# STM32H5E5xx register map
File version: 1.0
Registers are 32-bit, read-write, reset 0x0 unless marked. A register's access mark holds for its fields unless they carry their own. Offsets are from the block's base; [hi:lo] are bit positions; {n}, {i} and the like mark numbered series.

## PWR — Power Control
Base 0x44020800
Same registers: PWR_S 0x54020800
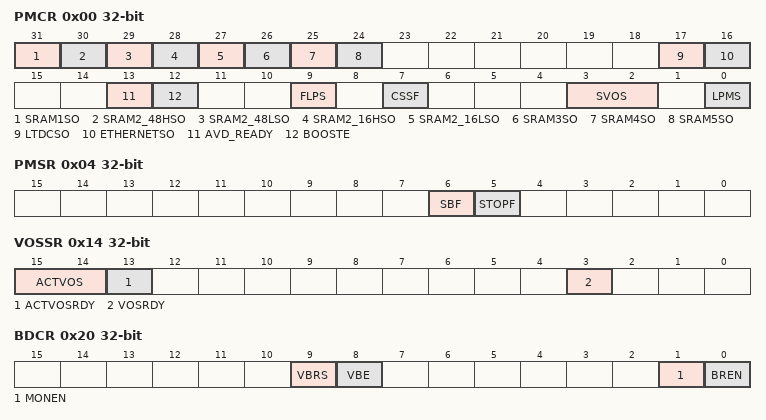
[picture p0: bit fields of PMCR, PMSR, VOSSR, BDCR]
0x00 PMCR — Power mode control register
  [31] SRAM1SO
  [30] SRAM2_48HSO
  [29] SRAM2_48LSO
  [28] SRAM2_16HSO
  [27] SRAM2_16LSO
  [26] SRAM3SO
  [25] SRAM4SO
  [24] SRAM5SO
  [17] LTDCSO
  [16] ETHERNETSO
  [13] AVD_READY
  [12] BOOSTE
  [9] FLPS
  [7] CSSF
  [3:2] SVOS
    3=SCALE3 (Select voltage scale 3 when system enters STOP mode); 2=SCALE4 (Select voltage scale 4 when system enters STOP mode); 1=SCALE5 (Select voltage scale 5 when system enters STOP mode)
  [0] LPMS
    0=STOP_MODE (STOP 0 mode); 1=STANDBY_MODE
0x04 PMSR — Power mode status register
  [6] SBF, [5] STOPF
0x10 VOSCR — Voltage scaling control register
  [5:4] VOS
    3=SCALE0 (Voltage scaling range 0); 2=SCALE1 (Voltage scaling range 1); 1=SCALE2 (Voltage scaling range 2); 0=SCALE3 (Voltage scaling range 3)
0x14 VOSSR — Voltage sacling status register
  [15:14] ACTVOS, [13] ACTVOSRDY, [3] VOSRDY
0x20 BDCR — BacKup domain control register
  [9] VBRS
    0=RESISTOR_5K (Charge the battery through a 5 kO resistor); 1=RESISTOR_1_5K (Charge the battery through a 1.5 kO resistor)
  [8] VBE
  [1] MONEN
  [0] BREN
0x24 DBPCR — DBP control register
  [0] DBP
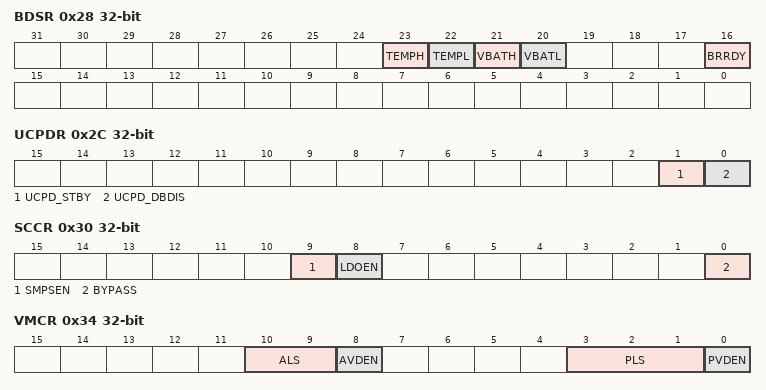
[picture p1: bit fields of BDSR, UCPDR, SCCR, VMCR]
0x28 BDSR — BacKup domain status register
  [23] TEMPH, [22] TEMPL, [21] VBATH, [20] VBATL, [16] BRRDY
0x2C UCPDR — Usb typeC and Power Delivery Register
  [1] UCPD_STBY, [0] UCPD_DBDIS
0x30 SCCR — Supply configuration control register
  [9] SMPSEN, [8] LDOEN, [0] BYPASS
0x34 VMCR — Voltage Monitor Control Register
  [10:9] ALS
    0=AVDLEVEL_0 (Analog Voltage threshold detected by AVD 1.7 V); 1=AVDLEVEL_1 (Analog Voltage threshold detected by AVD 2.1 V); 2=AVDLEVEL_2 (Analog Voltage threshold detected by AVD 2.5 V); 3=AVDLEVEL_3 (Analog Voltage threshold detected by AVD 2.8 V)
  [8] AVDEN
  [3:1] PLS
    0=PVDLEVEL_0 (Voltage threshold detected by PVD 1.95 V); 1=PVDLEVEL_1 (Voltage threshold detected by PVD 2.10 V); 2=PVDLEVEL_2 (Voltage threshold detected by PVD 2.25 V); 3=PVDLEVEL_3 (Voltage threshold detected by PVD 2.40 V); 4=PVDLEVEL_4 (Voltage threshold detected by PVD 2.55 V); 5=PVDLEVEL_5 (Voltage threshold detected by PVD 2.70 V); 6=PVDLEVEL_6 (Voltage threshold detected by PVD 2.85 V); 7=PVDLEVEL_7
  [0] PVDEN
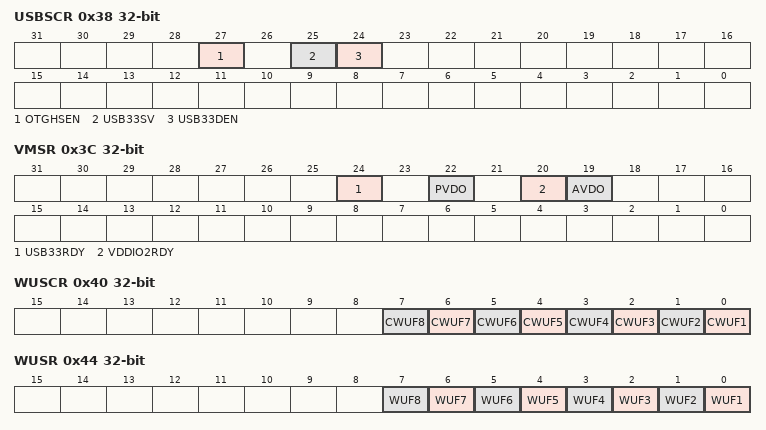
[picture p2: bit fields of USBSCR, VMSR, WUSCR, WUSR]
0x38 USBSCR — USB Supply Control Register
  [27] OTGHSEN, [25] USB33SV, [24] USB33DEN
0x3C VMSR — Status Register Voltage Monitoring
  [24] USB33RDY, [22] PVDO, [20] VDDIO2RDY, [19] AVDO
0x40 WUSCR — WakeUP status clear register
  [n-1] CWUF{n} (n=1..8)
0x44 WUSR — WakeUP status Register
  [n-1] WUF{n} (n=1..8)
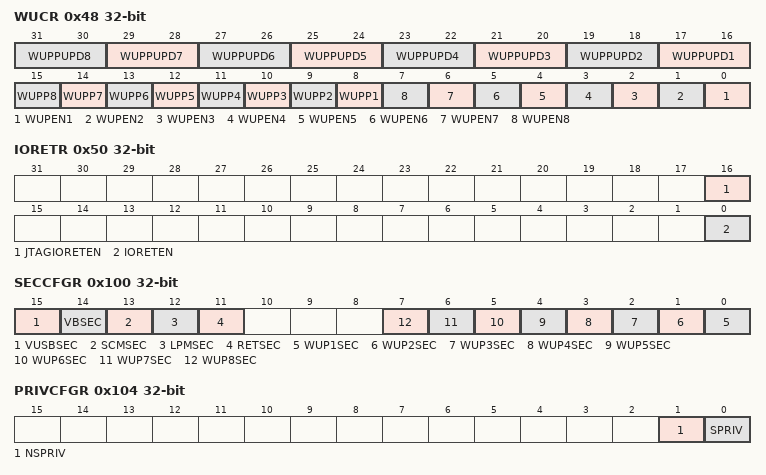
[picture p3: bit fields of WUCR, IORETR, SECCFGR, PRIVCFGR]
0x48 WUCR — WakeUP configuration register
  [2n+15:2n+14] WUPPUPD{n} (n=1..8), [n+7] WUPP{n} (n=1..8), [n-1] WUPEN{n} (n=1..8)
0x50 IORETR — IO RETention Register
  [16] JTAGIORETEN, [0] IORETEN
0x100 SECCFGR — Security configuration register
  [15] VUSBSEC, [14] VBSEC, [13] SCMSEC, [12] LPMSEC, [11] RETSEC, [n-1] WUP{n}SEC (n=1..8)
0x104 PRIVCFGR — Privilege configuration register
  [1] NSPRIV, [0] SPRIV

## DBGMCU — Debug MCU
Base 0x44024000
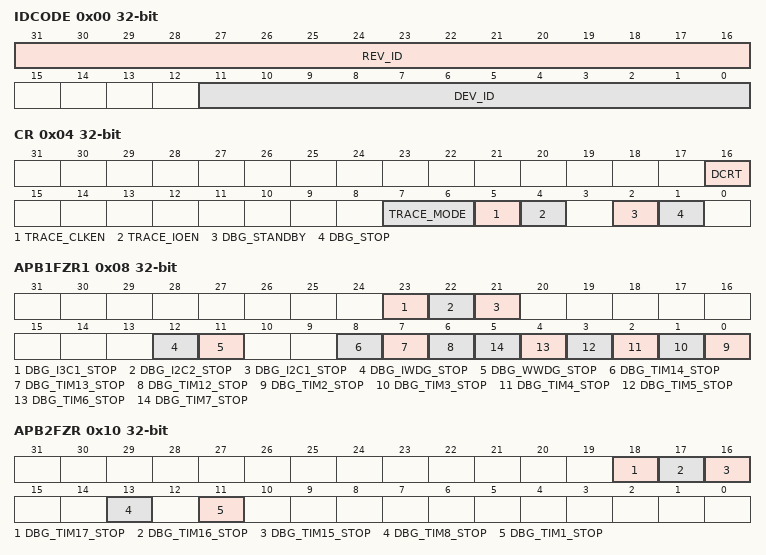
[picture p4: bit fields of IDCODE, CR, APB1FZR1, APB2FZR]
0x00 IDCODE — MCU device ID code
  [31:16] REV_ID, [11:0] DEV_ID
0x04 CR — Debug MCU configuration register
  [16] DCRT, [7:6] TRACE_MODE, [5] TRACE_CLKEN, [4] TRACE_IOEN, [2] DBG_STANDBY, [1] DBG_STOP
0x08 APB1FZR1 — Debug MCU APB1 freeze register 1
  [23] DBG_I3C1_STOP, [22] DBG_I2C2_STOP, [21] DBG_I2C1_STOP, [12] DBG_IWDG_STOP, [11] DBG_WWDG_STOP, [8] DBG_TIM14_STOP, [7] DBG_TIM13_STOP, [6] DBG_TIM12_STOP, [n-2] DBG_TIM{n}_STOP (n=2..7)
0x0C APB1FZR2 — Debug MCU APB1 freeze register 2
  [5] DBG_LPTIM2_STOP
0x10 APB2FZR — Debug MCU APB2 freeze register
  [18] DBG_TIM17_STOP, [17] DBG_TIM16_STOP, [16] DBG_TIM15_STOP, [13] DBG_TIM8_STOP, [11] DBG_TIM1_STOP
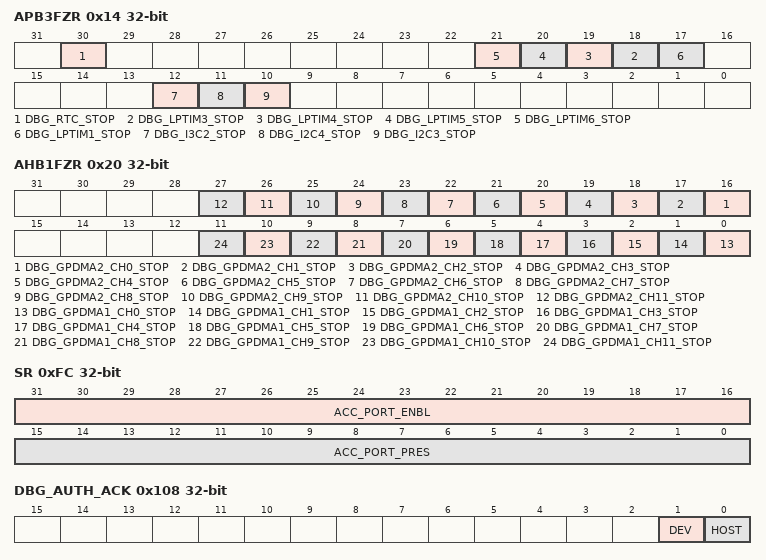
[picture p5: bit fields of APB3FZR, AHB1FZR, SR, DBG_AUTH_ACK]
0x14 APB3FZR — Debug MCU APB3 freeze register
  [30] DBG_RTC_STOP, [n+15] DBG_LPTIM{n}_STOP (n=3..6), [17] DBG_LPTIM1_STOP, [12] DBG_I3C2_STOP, [11] DBG_I2C4_STOP, [10] DBG_I2C3_STOP
0x20 AHB1FZR — Debug MCU AHB1 freeze register
  [n+16] DBG_GPDMA2_CH{n}_STOP (n=0..11), [n] DBG_GPDMA1_CH{n}_STOP (n=0..11)
0xFC SR — Debug MCU SR register
  [31:16] ACC_PORT_ENBL, [15:0] ACC_PORT_PRES
0x100 DBG_AUTH_HOST — Debug DBG_AUTH_HOST register
0x104 DBG_AUTH_DEV — Debug DBG_AUTH_DEV register
0x108 DBG_AUTH_ACK — Debug DBG_AUTH_ACK register
  [1] DEV, [0] HOST
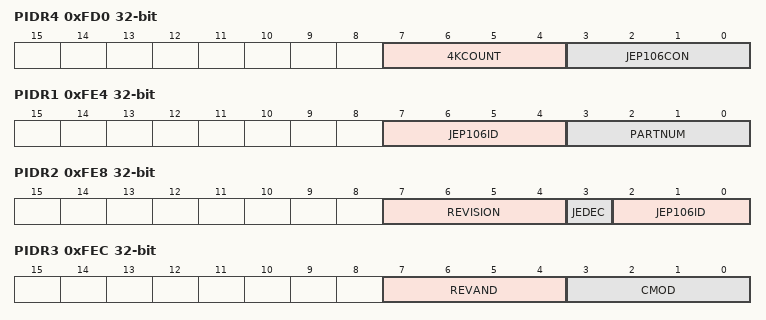
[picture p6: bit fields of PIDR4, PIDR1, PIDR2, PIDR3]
0xFD0 PIDR4 — Debug MCU Peripheral ID register 4
  [7:4] 4KCOUNT, [3:0] JEP106CON
{0xFC0+4i} PIDR{i} (i=5..7) — Debug MCU Peripheral ID register {i}
0xFE0 PIDR0 — Debug MCU Peripheral ID register 0
  [7:0] PARTNUM
0xFE4 PIDR1 — Debug MCU Peripheral ID register 1
  [7:4] JEP106ID, [3:0] PARTNUM
0xFE8 PIDR2 — Debug MCU Peripheral ID register 2
  [7:4] REVISION, [3] JEDEC, [2:0] JEP106ID
0xFEC PIDR3 — Debug MCU Peripheral ID register 3
  [7:4] REVAND, [3:0] CMOD
0xFF0 CIDR0 — Debug MCU Component ID register 0
  [7:0] PREAMBLE
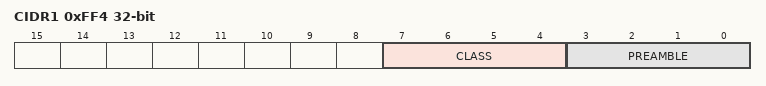
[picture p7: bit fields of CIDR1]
0xFF4 CIDR1 — Debug MCU Component ID register 1
  [7:4] CLASS, [3:0] PREAMBLE
0xFF8 CIDR2 — Debug MCU Component ID register 2
  [7:0] PREAMBLE
0xFFC CIDR3 — Debug MCU Component ID register 3
  [7:0] PREAMBLE
